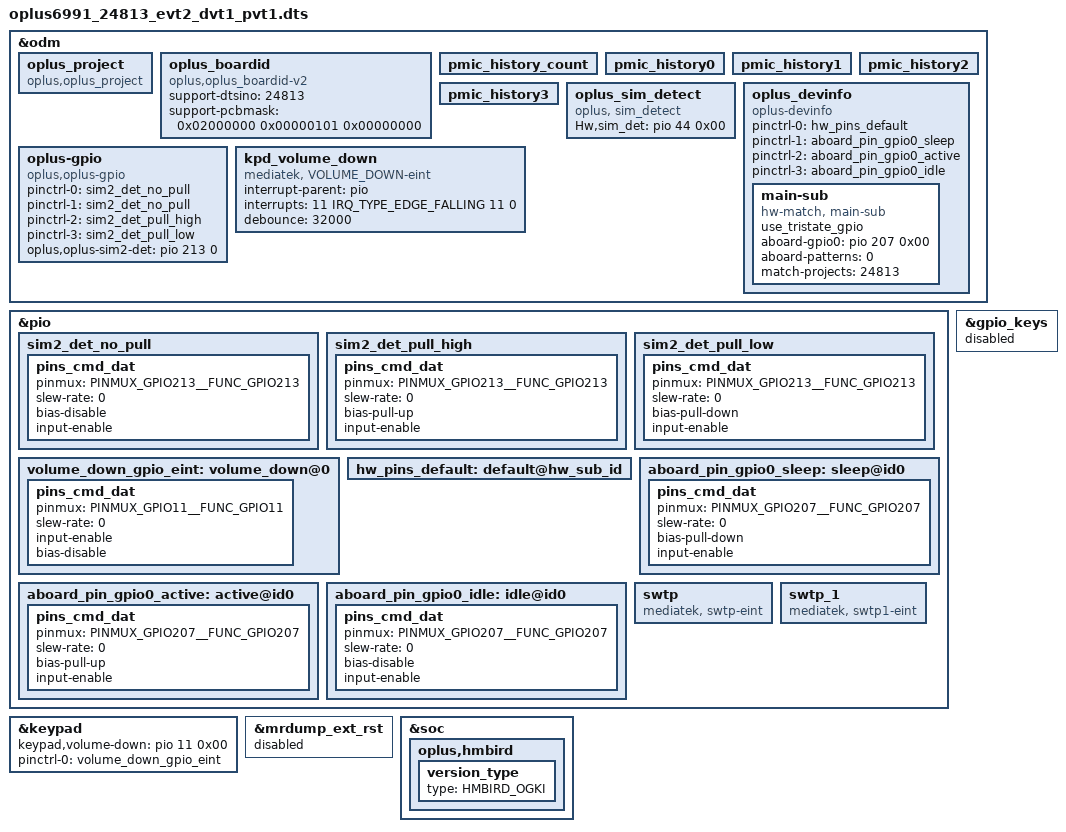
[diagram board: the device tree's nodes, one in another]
// SPDX-License-Identifier: (GPL-2.0 OR MIT)
/*
 * Copyright (C) 2022 MediaTek Inc.
 */
#include "k6991v1_64.dts"
/* #ifdef OPLUS_FEATURE_CHG_BASIC */
#include "mediatek/oplus_chg/oplus_charge_24813.dtsi"
#include "mediatek/oplus_chg/oplus_charge_24813_sili_EVT2.dtsi"
#include "mediatek/oplus_chg/oplus-chg-24813-pps.dtsi"
/* #endif */

/* #ifdef OPLUS_FEATURE_CHG_BASIC */
/* Add for DX-4 charge device-tree */
#include "mediatek/oplus_misc_24813.dtsi"
/* #endif */

/* #ifdef OPLUS_FEATURE_SENSOR */
#include "mediatek/oplus_sensor_24813.dtsi"
/* #endif */

/* Add for DX-4 ppb device-tree of VS1-BYP solution */
#include "mediatek/oplus_ppb_24813_VS1_BYP.dtsi"
/* #endif */

#include <dt-bindings/pinctrl/mt6373-pinfunc.h>

/* #ifdef OPLUS_DISPLAY_FEATURE */
#include "mediatek/oplus-display/mt6991-emira-24813-display-overlay.dtsi"
/* #endif */
&odm {
	/*OPLUS_FEATURE_OEM_OCDT oppo project start */
	oplus_project:oplus_project {
		compatible = "oplus,oplus_project";
    };

    oplus_boardid:oplus_boardid {
        compatible = "oplus,oplus_boardid-v2";
        support-dtsino=<24813>;//only one u32
        /*first one is low 32bit, last one is highest 32bit, must be 32-bit for 4gpios*/
        support-pcbmask=<0x02000000 0x00000101 0x00000000>;
    };

    pmic_history_count:pmic_history_count {
    };
    pmic_history0:pmic_history0 {
    };
    pmic_history1:pmic_history1 {
    };
    pmic_history2:pmic_history2 {
    };
    pmic_history3:pmic_history3 {
    };
};

&odm {
/* Add for sim detect */
    oplus_sim_detect {
        compatible = "oplus, sim_detect";
        Hw,sim_det = <&pio 44 0x00>;
    };
};

&odm {

        oplus_devinfo:oplus_devinfo {
                compatible = "oplus-devinfo";
                pinctrl-names = "default", "aboard_gpio0_sleep", "aboard_gpio0_active", "aboard_gpio0_idle";
                pinctrl-0 = <&hw_pins_default>;
                pinctrl-1 = <&aboard_pin_gpio0_sleep>;
                pinctrl-2 = <&aboard_pin_gpio0_active>;
                pinctrl-3 = <&aboard_pin_gpio0_idle>;
                main-sub {
                        use_tristate_gpio;
                        compatible = "hw-match, main-sub";
                        aboard-gpio0 = <&pio 207 0x00>;
                        aboard-patterns = <0>;        //0[high-resistance] 1[pull-down] 2[pull-up]
                        //main board
                        match-projects = <24813>;
                };
        };

};

//#ifdef OPLUS_FEATRUE_SIM_DETECT
&odm {
    oplus-gpio {
        compatible = "oplus,oplus-gpio";
        pinctrl-names = "default", "sim2_det_no_pull", "sim2_det_pull_high", "sim2_det_pull_low";
        pinctrl-0 = <&sim2_det_no_pull>;
        pinctrl-1 = <&sim2_det_no_pull>;
        pinctrl-2 = <&sim2_det_pull_high>;
        pinctrl-3 = <&sim2_det_pull_low>;
        oplus,oplus-sim2-det = <&pio 213 0>;
    };
};

&pio {
    sim2_det_no_pull: sim2_det_no_pull {
        pins_cmd_dat {
            pinmux = <PINMUX_GPIO213__FUNC_GPIO213>;
            slew-rate = <0>;
            bias-disable; /* NO pull */
            input-enable;
        };
    };

    sim2_det_pull_high: sim2_det_pull_high {
        pins_cmd_dat {
            pinmux = <PINMUX_GPIO213__FUNC_GPIO213>;
            slew-rate = <0>;
            bias-pull-up;
            input-enable;
        };
    };

    sim2_det_pull_low: sim2_det_pull_low {
        pins_cmd_dat {
            pinmux = <PINMUX_GPIO213__FUNC_GPIO213>;
            slew-rate = <0>;
            bias-pull-down;
            input-enable;
        };
    };
};

&keypad {
        keypad,volume-down = <&pio 11 0x00>;
        pinctrl-names = "volume_down_as_int";
        pinctrl-0 = <&volume_down_gpio_eint>;
        status = "okay";
};

&pio {
        volume_down_gpio_eint:volume_down@0{
                pins_cmd_dat {
                        pinmux = <PINMUX_GPIO11__FUNC_GPIO11>;
                        slew-rate = <0>;  /*direction 0:in, 1:out*/
                        input-enable;
                        bias-disable;
                };
        };
};

&odm {
        kpd_volume_down:kpd_volume_down {
                compatible = "mediatek, VOLUME_DOWN-eint";
                interrupt-parent = <&pio>;
                interrupts = <11 IRQ_TYPE_EDGE_FALLING 11 0>;
                debounce = <32000>;
                status = "okay";
        };
};

&gpio_keys {
    status = "disabled";
};

&pio{
        hw_pins_default:default@hw_sub_id {
	};

        aboard_pin_gpio0_sleep:sleep@id0 {
		pins_cmd_dat {
			pinmux = <PINMUX_GPIO207__FUNC_GPIO207>;
			slew-rate = <0>;
			bias-pull-down;
			input-enable;
		};
	};

	aboard_pin_gpio0_active:active@id0 {
		pins_cmd_dat {
			pinmux = <PINMUX_GPIO207__FUNC_GPIO207>;
			slew-rate = <0>;
			bias-pull-up;
			input-enable;
		};
	};

	aboard_pin_gpio0_idle:idle@id0 {
		pins_cmd_dat {
			pinmux = <PINMUX_GPIO207__FUNC_GPIO207>;
			slew-rate = <0>;
			bias-disable;
			input-enable;
		};
	};
};

&pio {
	//#ifdef OPLUS_VENDOR_SWTP
	swtp: swtp {
		compatible = "mediatek, swtp-eint";
	};
	 swtp_1: swtp_1 {
        compatible = "mediatek, swtp1-eint";
    };
	//#endif  /*OPLUS_VENDOR_SWTP*/
};

&mrdump_ext_rst	{
	status = "disabled";
};

&soc {
    //#ifdef CONFIG_HMBIRD_SCHED
    oplus,hmbird {
        version_type {
            type = "HMBIRD_OGKI";
        };
    };
    //#endif /* CONFIG_HMBIRD_SCHED */
};

#include "mediatek/cust_mt6991_emira_camera_v4l2.dtsi"
#include <oplus6991_24813/cust.dtsi>
#include "mediatek/cust_mt6991_emira_audio.dtsi"
#include "mediatek/cust_mt6991_vow_breeno.dtsi"
#include "mediatek/nfc/mt6991_24813_thn31s.dtsi"
#include "mediatek/wifi_bt_fem/mt6991_fem_2G_2A.dtsi"
#include "mediatek/wifi_bt_fem/mt6991_fem_2G_2A_vc5364_5768.dtsi"
#include "mediatek/oplus_tp_24813.dtsi"
/* #ifdef CONFIG_UFF_FINGERPRINT */
#include "mediatek/oplus_uff_24813.dtsi"
/* #endif CONFIG_UFF_FINGERPRINT */
#include "mediatek/cust_mt6991_thermal.dtsi"
#include "mediatek/cust_mt6991_emira_thermal.dtsi"
/*End of this file, DO NOT ADD ANYTHING HERE*/

